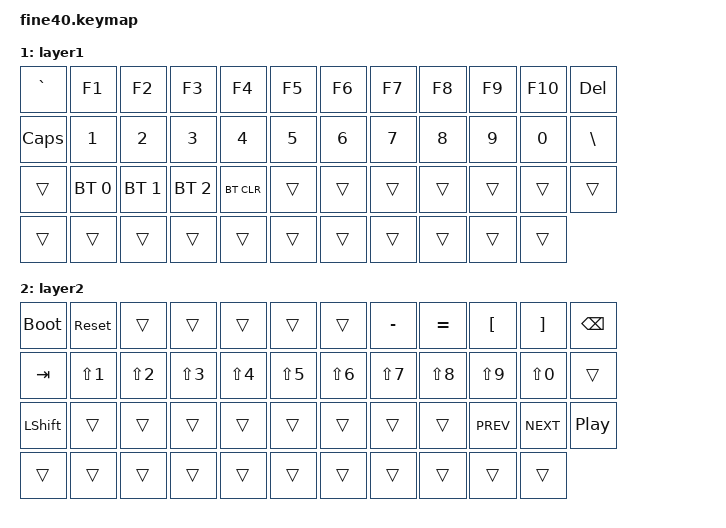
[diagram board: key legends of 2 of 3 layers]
#include <behaviors.dtsi>
#include <dt-bindings/zmk/keys.h>
#include <dt-bindings/zmk/bt.h>
#include <dt-bindings/zmk/ext_power.h>

#define DEFAULT 0
#define MO1     1
#define MO2     2

/ {
	keymap {
		compatible = "zmk,keymap";

		default_layer {
            // -----------------------------------------------------------------------------------------
            // |  ESC  |  Q   |  W   |  E   |  R   |  T   |   Y   |  U    |  I   |  O   |   P   | BSPC  |
            // |  TAB  |  A   |  S   |  D   |  F   |  G   |   H   |  J    |  K   |  L   |   ;   |  '    |
            // | SHIFT |  Z   |  X   |  C   |  V   |  B   |   N   |  M    |  ,   |  .   |   /   |  RET  |
            // | LCTL  | LGUI | LALT |  MO1 |  SPC | SPC/MO2  | LARW | DARW | UARW  |  RARW |  P/P  |

			bindings = <
				&kp ESC   &kp Q    &kp W    &kp E    &kp R     &kp T     &kp Y     &kp U    &kp I     &kp O    &kp P      &kp BSPC
				&kp TAB   &kp A    &kp S    &kp D    &kp F     &kp G     &kp H     &kp J    &kp K     &kp L    &kp SEMI   &kp SQT
				&kp LSHFT &kp Z    &kp X    &kp C    &kp V     &kp B     &kp N     &kp M    &kp COMMA &kp DOT  &kp FSLH   &kp RET
				&kp LCTL  &kp LGUI &kp LALT &mo MO1  &kp SPC   &none	 &lt MO2 SPC        &kp LEFT  &kp DOWN &kp UP     &kp RIGHT &kp C_MUTE
			>;

			sensor-bindings = <&inc_dec_kp C_VOL_UP C_VOL_DN>;
		};

        layer1 {
			bindings = <
				&kp GRAVE &kp F1   &kp F2   &kp F3   &kp F4    &kp F5    &kp F6    &kp F7   &kp F8    &kp F9   &kp F10    &kp DEL
				&kp CAPS  &kp N1   &kp N2   &kp N3   &kp N4    &kp N5    &kp N6    &kp N7   &kp N8    &kp N9   &kp N0     &kp BSLH
				&trans    &bt BT_SEL 0      &bt BT_SEL 1       &bt BT_SEL 2        &bt BT_CLR         &trans   &trans     &trans     &trans   &trans    &trans   &trans
				&trans    &trans   &trans   &trans   &trans    &trans    &trans    &trans   &trans	  &trans   &trans
			>;
		};

        layer2 {
			bindings = <
				&bootloader  &sys_reset     	&trans     &trans     &trans     &trans     &trans     &kp MINUS  &kp EQUAL   &kp LBKT   &kp RBKT   &kp BSPC
				&kp TAB   &kp LS(N1) &kp LS(N2) &kp LS(N3) &kp LS(N4) &kp LS(N5) &kp LS(N6) &kp LS(N7) &kp LS(N8) &kp LS(N9) &kp LS(N0) &trans
				&kp LSHFT &trans     &trans     &trans     &trans     &trans     &trans     &trans     &trans     &kp C_PREV &kp C_NEXT &kp C_PP
				&trans    &trans     &trans     &trans     &trans     &trans     &trans     &trans     &trans	  &trans 	 &trans
			>;
		};
	};
};

